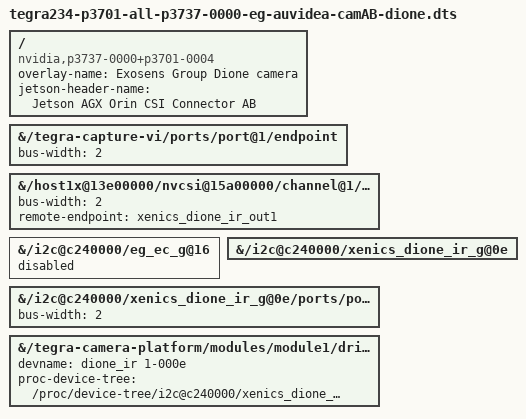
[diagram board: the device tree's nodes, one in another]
// SPDX-License-Identifier: GPL-2.0-only
/*
 * Jetson Device-tree overlay for Camera E3331 on t23x platforms
 *
 * Copyright (c) 2022 NVIDIA CORPORATION. All rights reserved.
 *
 */


/dts-v1/;
/plugin/;


/ {
	overlay-name = "Exosens Group Dione camera";
	jetson-header-name = "Jetson AGX Orin CSI Connector AB";
	compatible = "nvidia,p3737-0000+p3701-0004", "nvidia,tegra234", "nvidia,tegra23x";

	fragment@0 {
		target-path = "/tegra-capture-vi/ports/port@1/endpoint";
		__overlay__ {
			bus-width=<2>;
		};
	};

	fragment@1 {
		target-path = "/host1x@13e00000/nvcsi@15a00000/channel@1/ports/port@0/endpoint@0";
		__overlay__ {
			bus-width=<2>;
         remote-endpoint = <&xenics_dione_ir_out1>;
		};
	};

   // Disable EngineCore cameras
	fragment@3 {
		target-path = "/i2c@c240000/eg_ec_g@16";
		__overlay__ {
         status = "disabled";
		};
	};

   // Enable Dione cameras
	fragment@2 {
		target-path = "/i2c@c240000/xenics_dione_ir_g@0e";
		__overlay__ {
         status = "okay";
		};
	};
	fragment@4 {
		target-path = "/i2c@c240000/xenics_dione_ir_g@0e/ports/port@0/endpoint";
		__overlay__ {
			bus-width=<2>;
		};
	};

	fragment@5 {
		target-path = "/tegra-camera-platform/modules/module1/drivernode0";
		__overlay__ {
         devname = "dione_ir 1-000e";
         proc-device-tree = "/proc/device-tree/i2c@c240000/xenics_dione_ir_g@0e";
		};
	};
};
